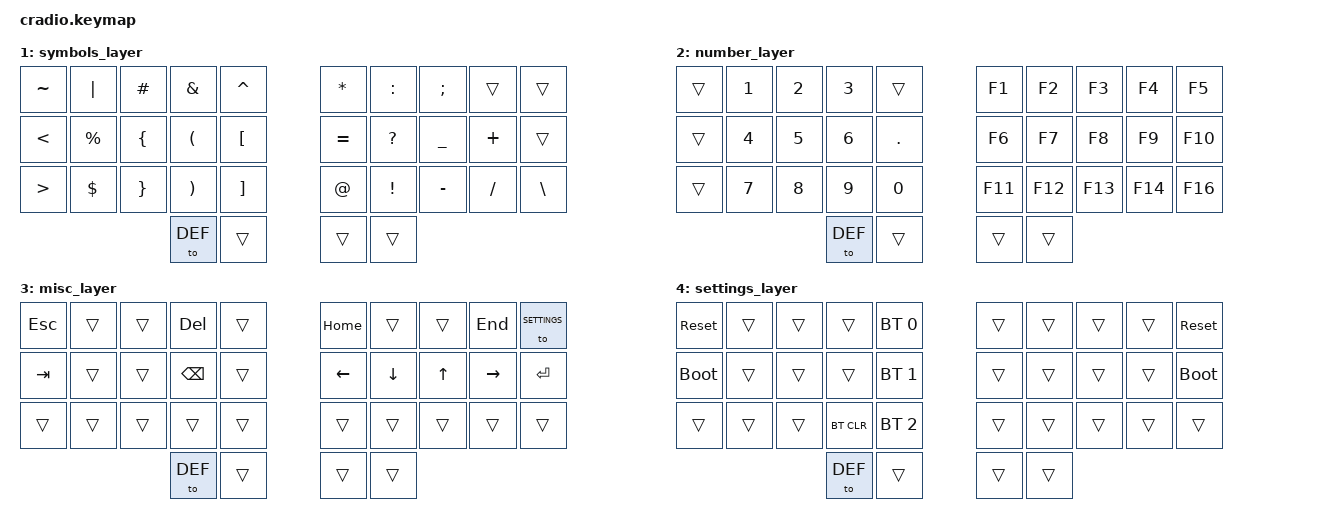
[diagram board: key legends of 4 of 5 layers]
// Copyright (c) 2022 The ZMK Contributors
// SPDX-License-Identifier: MIT

#include <behaviors.dtsi>
#include <dt-bindings/zmk/keys.h>
#include <dt-bindings/zmk/bt.h>
#include <dt-bindings/zmk/outputs.h>

// Home row mods macro
#define HRML(k1,k2,k3,k4) &ht LSHFT k1  &ht LALT k2  &ht LCTRL k3  &ht LGUI k4
#define HRMR(k1,k2,k3,k4) &ht RGUI k1  &ht RCTRL k2  &ht RALT k3  &ht RSHFT k4
#define WHRML(k2,k3,k4) &ht LALT k2  &ht LGUI k3  &ht LCTRL k4
#define WHRMR(k1,k2,k3) &ht RCTRL k1  &ht RGUI k2  &ht RALT k3

#define DEF 0
#define SYM 1
#define NUM 2
#define MISC 3
#define SETTINGS 4

/ {

    combos {
        compatible = "zmk,combos";
        combo_esc {
            timeout-ms = <50>;
            key-positions = <2 3>;
            bindings = <&kp ESC>;
        };
        combo_caps {
            timeout-ms = <50>;
            key-positions = <24 25>;
            bindings = <&caps_word>;
        };
        combo_backspace {
            timeout-ms = <50>;
            key-positions = <16 17>;
            bindings = <&kp BSPC>;
        };
        combo_enter {
            timeout-ms = <50>;
            key-positions = <6 7>;
            bindings = <&kp ENTER>;
        };
        combo_del {
            timeout-ms = <50>;
            key-positions = <26 27>;
            bindings = <&kp DEL>;
        };
        combo_tab {
            timeout-ms = <50>;
            key-positions = <12 13>;
            bindings = <&kp TAB>;
        };
        combo_copy {
            timeout-ms = <50>;
            key-positions = <1 3>;
            bindings = <&kp LC(C)>;
        };
        combo_paste {
            timeout-ms = <50>;
            key-positions = <11 13>;
            bindings = <&kp LC(V)>;
        };
        combo_cut {
            timeout-ms = <50>;
            key-positions = <21 23>;
            bindings = <&kp LC(X)>;
        };
    };

    behaviors {
            ht: hold_tap {
                label = "hold_tap";
                compatible = "zmk,behavior-hold-tap";
                #binding-cells = <2>;
                flavor = "tap-preferred";
                tapping-term-ms = <190>;
                quick-tap-ms = <0>;
                global-quick-tap;
                bindings = <&kp>, <&kp>;
            };

            td0: tap_dance_0 {
            compatible = "zmk,behavior-tap-dance";
            #binding-cells = <0>;
            tapping-term-ms = <200>;
            bindings = <&kp LSHFT>, <&to NUM>;
            };
            td1: tap_dance_1 {
            compatible = "zmk,behavior-tap-dance";
            #binding-cells = <0>;
            tapping-term-ms = <200>;
            bindings = <&mo SYM>, <&to MISC>;
            };
        };

    keymap {
        compatible = "zmk,keymap";
default_layer {
            bindings = <
        //╭──────────┬──────────┬──────────┬──────────┬──────────╮   ╭──────────┬──────────┬──────────┬──────────┬──────────╮
        //│  Q       │  W       │  E       │  R       │  T       │   │  Y       │  U       │  I       │  O       │  P       │
            &kp Q      &kp W      &kp E      &kp R      &kp T          &kp Y      &kp U      &kp I      &kp O      &kp P
        //├──────────┼──────────┼──────────┼──────────┼──────────┤   ├──────────┼──────────┼──────────┼──────────┼──────────┤
        //│  A       │  S       │  D       │  F       │  G       │   │  H       │  J       │  K       │  L       │   ' "    │
             HRML(A,       S,         D,         F)     &kp G          &kp H      HRMR(J,        K,           L,      SQT)
        //├──────────┼──────────┼──────────┼──────────┼──────────┤   ├──────────┼──────────┼──────────┼──────────┼──────────┤
        //│  Z       │  X       │  C       │  V       │  B       │   │  N       │  M       │ , <      │ . >      │          │
            &kp Z      &kp X      &kp C      &kp V      &kp B          &kp N      &kp M      &kp COMMA  &kp DOT    &kp ENTER
        //╰──────────┴──────────┴──────────┼──────────┼──────────┤   ├──────────┼──────────┼──────────┴──────────┴──────────╯
                                             &lt NUM DEF  &kp LSHFT   &kp SPACE   &td1
        //                                 ╰──────────┴──────────╯   ╰──────────┴──────────╯
            >;
        };
        

symbols_layer {
            bindings = <
        //╭──────────┬──────────┬──────────┬──────────┬──────────╮   ╭──────────┬──────────┬──────────┬──────────┬──────────╮
        //│          │          │          │          │          │   │          │          │          │          │          │
           &kp TILDE  &kp PIPE   &kp HASH   &kp AMPS   &kp CARET       &kp STAR  &kp COLON  &kp SEMI   &trans       &trans 
        //├──────────┼──────────┼──────────┼──────────┼──────────┤   ├──────────┼──────────┼──────────┼──────────┼──────────┤
        //│          │          │          │          │          |   |          │          │          │          │          │
            &kp LT    &kp PRCNT   &kp LBRC   &kp LPAR   &kp LBKT      &kp EQUAL  &kp QMARK  &kp UNDER   &kp PLUS   &trans 
        //├──────────┼──────────┼──────────┼──────────┼──────────┤   ├──────────┼──────────┼──────────┼──────────┼──────────┤
        //│          │          │          │          │          │   │          │          │          │          │          │
            &kp GT    &kp DLLR    &kp RBRC   &kp RPAR   &kp RBKT      &kp AT     &kp EXCL   &kp MINUS   &kp FSLH   &kp BSLH  
        //╰──────────┴──────────┴──────────┼──────────┼──────────┤   ├──────────┼──────────┼──────────┴──────────┴──────────╯
                                             &to DEF     &trans        &trans     &trans
        //                                 ╰──────────┴──────────╯   ╰──────────┴──────────╯
            >;
        };

number_layer {
            bindings = <
        //╭──────────┬──────────┬──────────┬──────────┬──────────╮   ╭──────────┬──────────┬──────────┬──────────┬──────────╮
        //│          │          │          │          │          │   │          │          │          │          │          │
            &trans       &kp N1     &kp N2     &kp N3     &trans       &kp F1    &kp F2     &kp F3      &kp F4    &kp F5 
        //├──────────┼──────────┼──────────┼──────────┼──────────┤   ├──────────┼──────────┼──────────┼──────────┼──────────┤
        //│          │          │          │          │          │   │          │          │          │          │          │
           &trans        &kp N4     &kp N5     &kp N6     &kp DOT       &kp F6    &kp F7     &kp F8     &kp F9      &kp F10 
        //├──────────┼──────────┼──────────┼──────────┼──────────┤   ├──────────┼──────────┼──────────┼──────────┼──────────┤
        //│          │          │          │          │          │   │          │          │          │          │          │
            &trans     &kp N7     &kp N8    &kp N9     &kp N0          &kp F11     &kp F12    &kp F13    &kp F14    &kp F16 
        //╰──────────┴──────────┴──────────┼──────────┼──────────┤   ├──────────┼──────────┼──────────┴──────────┴──────────╯
                                             &to DEF     &trans         &trans   &trans
        //                                 ╰──────────┴──────────╯   ╰──────────┴──────────╯
            >;
        };

misc_layer {
            bindings = <
        //╭──────────┬──────────┬──────────┬──────────┬──────────╮   ╭──────────┬──────────┬──────────┬──────────┬──────────╮
        //│          │          │          │          │          │   │          │          │          │          │          │
           &kp ESC    &trans     &trans     &kp DEL       &trans       &kp HOME   &trans    &trans      &kp END       &to SETTINGS 
        //├──────────┼──────────┼──────────┼──────────┼──────────┤   ├──────────┼──────────┼──────────┼──────────┼──────────┤
        //│          │          │          │          │          │   │          │          │          │          │          │
           &kp TAB    &trans      &trans    &kp BSPC    &trans          &kp LEFT  &kp DOWN   &kp UP    &kp RIGHT      &kp ENTER 
        //├──────────┼──────────┼──────────┼──────────┼──────────┤   ├──────────┼──────────┼──────────┼──────────┼──────────┤
        //│          │          │          │          │          │   │          │          │          │          │          │
            &trans    &trans     &trans     &trans     &trans          &trans     &trans     &trans    &trans        &trans 
        //╰──────────┴──────────┴──────────┼──────────┼──────────┤   ├──────────┼──────────┼──────────┴──────────┴──────────╯
                                             &to  DEF   &trans        &trans     &trans
        //                                 ╰──────────┴──────────╯   ╰──────────┴──────────╯
            >;
        };

settings_layer {
            bindings = <
        //╭──────────┬──────────┬──────────┬──────────┬──────────╮   ╭──────────┬──────────┬──────────┬──────────┬──────────╮
        //│ RESET    │          │          │          │PROFILE 0 │   │          │          │          │          │  RESET   │
           &sys_reset  &trans     &trans     &trans    &bt BT_SEL 0    &trans     &trans     &trans     &trans    &sys_reset
        //├──────────┼──────────┼──────────┼──────────┼──────────┤   ├──────────┼──────────┼──────────┼──────────┼──────────┤
        //│BOOTLOADER│          │          │          │PROFILE 1 │   │          │          │          │          │BOOTLOADER│
          &bootloader  &trans     &trans     &trans    &bt BT_SEL 1    &trans     &trans     &trans     &trans    &bootloader
        //├──────────┼──────────┼──────────┼──────────┼──────────┤   ├──────────┼──────────┼──────────┼──────────┼──────────┤
        //│          │          │          │ CLEAR BT │PROFILE 2 │   │          │          │          │          │          │
            &trans     &trans     &trans    &bt BT_CLR &bt BT_SEL 2    &trans     &trans     &trans     &trans     &trans
        //╰──────────┴──────────┴──────────┼──────────┼──────────┤   ├──────────┼──────────┼──────────┴──────────┴──────────╯
                                             &to DEF     &trans         &trans     &trans
        //                                 ╰──────────┴──────────╯   ╰──────────┴──────────╯
            >;
        };
    };
};
